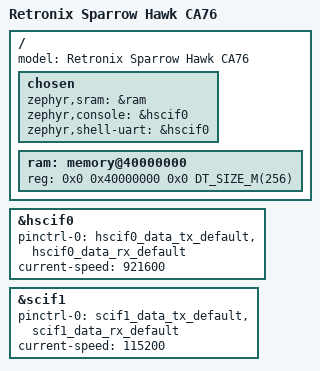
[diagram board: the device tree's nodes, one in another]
/*
 * Copyright (c) 2023-2024 EPAM Systems
 *
 * SPDX-License-Identifier: Apache-2.0
 *
 */

/dts-v1/;
#include <mem.h>
#include <arm64/renesas/r8a779g3.dtsi>
#include "rcar_sparrow_hawk_r8a779g3_a76-pinctrl.dtsi"

/ {
	model = "Retronix Sparrow Hawk CA76";
	chosen {
		zephyr,sram = &ram;
		zephyr,console = &hscif0;
		zephyr,shell-uart = &hscif0;
	};

	ram: memory@40000000 {
		device_type = "mmio-sram";
		reg = <0x0 0x40000000 0x0 DT_SIZE_M(256)>;
	};
};

&hscif0 {
	pinctrl-0 = <&hscif0_data_tx_default &hscif0_data_rx_default>;
	pinctrl-names = "default";
	current-speed = <921600>;
	status = "okay";
};

&scif1 {
	pinctrl-0 = <&scif1_data_tx_default &scif1_data_rx_default>;
	pinctrl-names = "default";
	current-speed = <115200>;
	status = "okay";
};

